# ADuCM4050 register map
Vendor: Analog Devices; Series: ADuCM4050; File version: 1p0
CPU: CM4 r0p1, little endian, MPU, FPU, 3 interrupt priority bits
Registers are 32-bit, read-write, reset 0x0 unless marked. A register's access mark holds for its fields unless they carry their own. Offsets are from the block's base; [hi:lo] are bit positions; {n}, {i} and the like mark numbered series.

## RTC0 — Real-Time Clock
Base 0x40001000
Same registers: RTC1 0x40001400
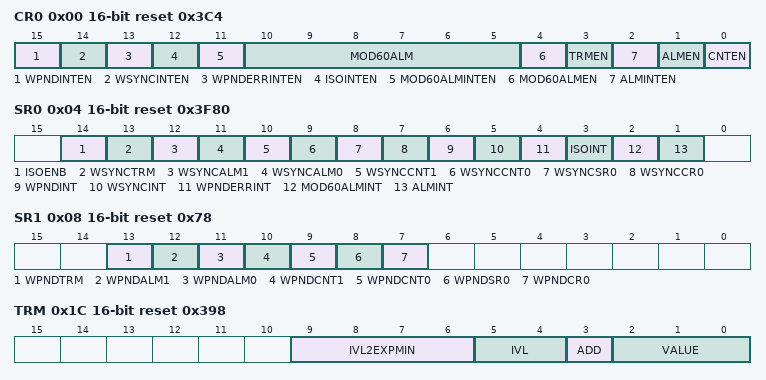
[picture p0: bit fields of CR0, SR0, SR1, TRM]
0x00 CR0 16-bit reset 0x3C4 — RTC Control 0
  [15] WPNDINTEN — Enable Write Pending Sourced Interrupts to the CPU
  [14] WSYNCINTEN — Enable Write Synchronization Sourced Interrupts to the CPU
  [13] WPNDERRINTEN — Enable Write Pending Error Sourced Interrupts to the CPU When an RTC Register-write Pending Error Occurs
  [12] ISOINTEN — Enable ISOINT Sourced Interrupts to the CPU When Isolation of the RTC Power Domain is Activated and Subsequently De-activated
  [11] MOD60ALMINTEN — Enable Periodic Modulo-60 RTC Alarm Sourced Interrupts to the CPU
  [10:5] MOD60ALM range 0x00000000..0x0000003F — Periodic, Modulo-60 Alarm Time in Prescaled RTC Time Units Beyond a Modulo-60 Boundary
  [4] MOD60ALMEN — Enable RTC Modulo-60 Counting of Time Past a Modulo-60 Boundary
  [3] TRMEN — Enable RTC Digital Trimming
  [2] ALMINTEN — Enable ALMINT Sourced Alarm Interrupts to the CPU
  [1] ALMEN — Enable the RTC Alarm (Absolute) Operation
  [0] CNTEN — Global Enable for the RTC
0x04 SR0 16-bit reset 0x3F80 — RTC Status 0
  [14] ISOENB ro — Visibility of 32kHz Sourced Registers
  [13] WSYNCTRM ro — Synchronisation Status of Posted Writes to TRM
  [12] WSYNCALM1 ro — Synchronisation Status of Posted Writes to ALM1
  [11] WSYNCALM0 ro — Synchronisation Status of Posted Writes to ALM0
  [10] WSYNCCNT1 ro — Synchronisation Status of Posted Writes to CNT1
  [9] WSYNCCNT0 ro — Synchronisation Status of Posted Writes to CNT0
  [8] WSYNCSR0 ro — Synchronisation Status of Posted Writes to SR0
  [7] WSYNCCR0 ro — Synchronisation Status of Posted Writes to CR0
  [6] WPNDINT — Write Pending Interrupt
  [5] WSYNCINT — Write Synchronisation Interrupt
  [4] WPNDERRINT — Write Pending Error Interrupt Source
  [3] ISOINT — RTC Power-Domain Isolation Interrupt Source
  [2] MOD60ALMINT — Modulo-60 RTC Alarm Interrupt Source
  [1] ALMINT — Alarm Interrupt Source
0x08 SR1 16-bit reset 0x78 — RTC Status 1
  [13] WPNDTRM ro — Pending Status of Posted Writes to TRM
  [12] WPNDALM1 ro — Pending Status of Posted Writes to ALM1
  [11] WPNDALM0 ro — Pending Status of Posted Writes to ALM0
  [10] WPNDCNT1 ro — Pending Status of Posted Writes to CNT1
  [9] WPNDCNT0 ro — Pending Status of Posted Writes to CNT0
  [8] WPNDSR0 ro — Pending Status of Posted Clearances of Interrupt Sources in SR0
  [7] WPNDCR0 ro — Pending Status of Posted Writes to CR0
0x0C CNT0 16-bit — RTC Count 0
  [15:0] VALUE range 0x00000000..0x0000FFFF — Lower 16 Prescaled (Non-Fractional) Bits of the RTC Real-Time Count
0x10 CNT1 16-bit — RTC Count 1
  [15:0] VALUE range 0x00000000..0x0000FFFF — Upper 16 Prescaled (Non-Fractional) Bits of the RTC Real-Time Count
0x14 ALM0 16-bit reset 0xFFFF — RTC Alarm 0
  [15:0] VALUE range 0x00000000..0x0000FFFF — Lower 16 Prescaled (i.e. Non-Fractional) Bits of the RTC Alarm Target Time
0x18 ALM1 16-bit reset 0xFFFF — RTC Alarm 1
  [15:0] VALUE range 0x00000000..0x0000FFFF — Upper 16 Prescaled (Non-Fractional) Bits of the RTC Alarm Target Time
0x1C TRM 16-bit reset 0x398 — RTC Trim
  [9:6] IVL2EXPMIN range 0x00000000..0x0000000F — Minimum Power-of-two Interval of Prescaled RTC Time Units Which TRM:TRMIVL TRMIVL Can Select
  [5:4] IVL — Trim Interval in Prescaled RTC Time Units
  [3] ADD — Trim Polarity
  [2:0] VALUE — Trim Value in Prescaled RTC Time Units to Be Added or Subtracted from the RTC Count at the End of a Periodic Interval Selected by TRM:TRMIVL
0x20 GWY 16-bit — RTC Gateway
  [15:0] SWKEY wo range 0x00000000..0x0000FFFF — Software-keyed Command Issued by the CPU
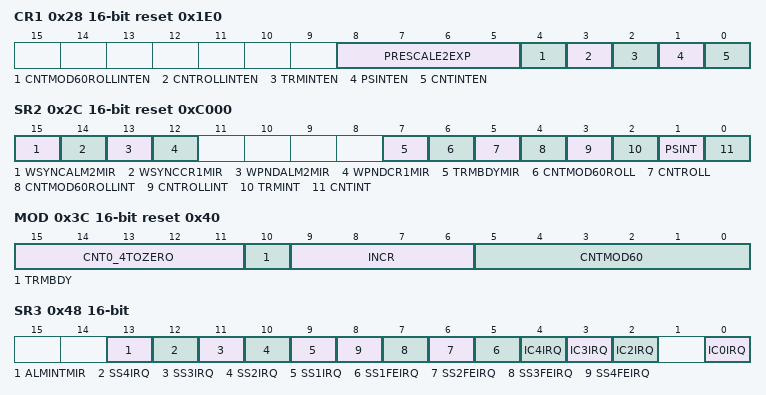
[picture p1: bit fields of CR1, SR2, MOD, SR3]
0x28 CR1 16-bit reset 0x1E0 — RTC Control 1
  [8:5] PRESCALE2EXP — Prescale Power of 2 Division Factor for the RTC Base Clock
  [4] CNTMOD60ROLLINTEN — Enable for the RTC Modulo-60 Count Roll-Over Interrupt Source
  [3] CNTROLLINTEN — Enable for the RTC Count Roll-Over Interrupt Source, in SR2:RTCCNTROLLINT
  [2] TRMINTEN — Enable for the RTC Trim Interrupt Source, in SR2:RTCTRMINT
  [1] PSINTEN — Enable for the Prescaled, Modulo-1 Interrupt Source, in SR2:RTCPSINT
  [0] CNTINTEN — Enable for the RTC Count Interrupt Source
0x2C SR2 16-bit reset 0xC000 — RTC Status 2
  [15] WSYNCALM2MIR ro — Synchronization Status of Posted Writes to ALM2
  [14] WSYNCCR1MIR ro — Synchronization Status of Posted Writes to CR1
  [13] WPNDALM2MIR ro — Pending Status of Posted Writes to ALM2
  [12] WPNDCR1MIR ro — Pending Status of Posted Writes to CR1
  [7] TRMBDYMIR ro — Mirror of MOD:RTCTRMBDY
  [6] CNTMOD60ROLL ro — RTC Count Modulo-60 Roll-Over
  [5] CNTROLL ro — RTC Count Roll-Over
  [4] CNTMOD60ROLLINT — RTC Modulo-60 Count Roll-Over Interrupt Source
  [3] CNTROLLINT — RTC Count Roll-Over Interrupt Source
  [2] TRMINT — RTC Trim Interrupt Source
  [1] PSINT — RTC Prescaled, Modulo-1 Boundary Interrupt Source
  [0] CNTINT — RTC Count Interrupt Source
0x30 SNAP0 16-bit — RTC Snapshot 0
  [15:0] VALUE ro — Constituent Part of the 47-bit Input Capture Channel 0, Containing a Sticky Snapshot of CNT0
0x34 SNAP1 16-bit — RTC Snapshot 1
  [15:0] VALUE ro — Part of the 47-bit Input Capture Channel 0 Containing a Sticky Snapshot of CNT1
0x38 SNAP2 16-bit — RTC Snapshot 2
  [14:0] VALUE ro — Part of the 47-bit Input Capture Channel 0 Containing a Sticky Snapshot of CNT2
0x3C MOD 16-bit reset 0x40 — RTC Modulo
  [15:11] CNT0_4TOZERO ro — Mirror of CNT0[4:0]
  [10] TRMBDY ro — Trim Boundary Indicator
  [9:6] INCR ro — Most Recent Increment Value Added to the RTC Count in CNT1 and CNT0
  [5:0] CNTMOD60 ro — Modulo-60 Value of the RTC Count: CNT1 and CNT0
0x40 CNT2 16-bit — RTC Count 2
  [14:0] VALUE ro — Fractional Bits of the RTC Real-Time Count
0x44 ALM2 16-bit — RTC Alarm 2
  [14:0] VALUE range 0x00000000..0x00007FFF — Fractional Bits of the Alarm Target Time
0x48 SR3 16-bit — RTC Status 3
  [13] ALMINTMIR ro — Read-only Mirror of the SR0:ALMINT Interrupt Source
  [12] SS4IRQ — Sticky Interrupt Source for the SensorStrobe Channel 4
  [11] SS3IRQ — Sticky Interrupt Source for the SensorStrobe Channel 3
  [10] SS2IRQ — Sticky Interrupt Source for the SensorStrobe Channel 2
  [9] SS1IRQ — Sticky Interrupt Source for SensorStrobe Channel 1
  [n+4] SS{n}FEIRQ (n=1..4) — Sticky Interrupt Source for the SensorStrobe Channel {n} Falling Edge
  [4] IC4IRQ — Sticky Interrupt Source for the RTC Input Capture Channel 4
  [3] IC3IRQ — Sticky Interrupt Source for the RTC Input Capture Channel 3
  [2] IC2IRQ — Sticky Interrupt Source for the RTC Input Capture Channel 2
  [0] IC0IRQ — Sticky Interrupt Source for the RTC Input Capture Channel 0
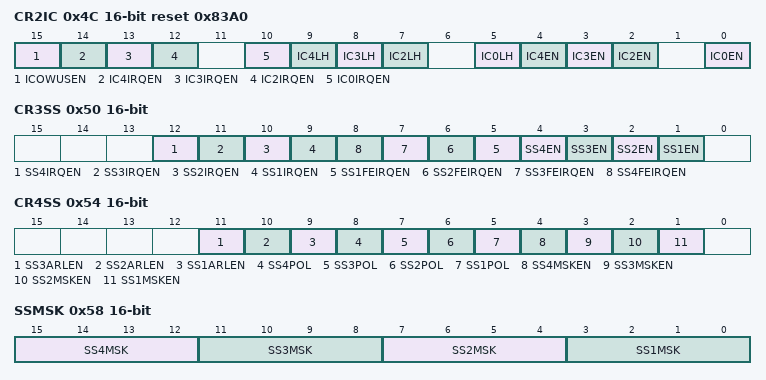
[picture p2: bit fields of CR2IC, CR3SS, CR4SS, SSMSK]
0x4C CR2IC 16-bit reset 0x83A0 — RTC Control 2 for Configuring Input Capture Channels
  [15] ICOWUSEN — Enable Overwrite of Unread Snapshots for All Input Capture Channels
  [14] IC4IRQEN — Interrupt Enable for the RTC Input Capture Channel 4
  [13] IC3IRQEN — Interrupt Enable for the RTC Input Capture Channel 3
  [12] IC2IRQEN — Interrupt Enable for the RTC Input Capture Channel 2
  [10] IC0IRQEN — Interrupt Enable for the RTC Input Capture Channel 0
  [9] IC4LH — Polarity of the Active-going Capture Edge for the Input Capture Channel 4
  [8] IC3LH — Polarity of the Active-going Capture Edge for the Input Capture Channel 3
  [7] IC2LH — Polarity of the Active-going Capture Edge for the Input Capture Channel 2
  [5] IC0LH — Polarity of the Active-Going Capture Edge for the RTC Input Capture Channel 0
  [4] IC4EN — Enable for the RTC Input Capture Channel 4
  [3] IC3EN — Enable for the RTC Input Capture Channel 3
  [2] IC2EN — Enable for the RTC Input Capture Channel 2
  [0] IC0EN — Enable for the RTC Input Capture Channel 0
0x50 CR3SS 16-bit — RTC Control 3 for Configuring SensorStrobe Channel
  [12] SS4IRQEN — Posedge EdgeInterrupt Enable for the SensorStrobe Channel 4
  [11] SS3IRQEN — Posedge EdgeInterrupt Enable for the SensorStrobe Channel 3
  [10] SS2IRQEN — Posedge EdgeInterrupt Enable for the SensorStrobe Channel 2
  [9] SS1IRQEN — Interrupt Enable for SensorStrobe Channel 1
  [n+4] SS{n}FEIRQEN (n=1..4) — Falling Edge Interrupt Enable for the SensorStrobe Channel {n}
  [4] SS4EN — Enable for the SensorStrobe Channel 4
  [3] SS3EN — Enable for the SensorStrobe Channel 3
  [2] SS2EN — Enable for the SensorStrobe Channel 2
  [1] SS1EN — Enable for SensorStrobe Channel 1
0x54 CR4SS 16-bit — RTC Control 4 for Configuring SensorStrobe Channel
  [11] SS3ARLEN — Enable for Fine Control on SensorStrobe Channel 3 Period and Duty Cycle
  [10] SS2ARLEN — Enable for Fine Control on SensorStrobe Channel 2 Period and Duty Cycle
  [9] SS1ARLEN — Enable for Fine Control on SensorStrobe Channel 1 Period and Duty Cycle
  [8] SS4POL — SensorStrobe Channel 4 Polarity Control
  [7] SS3POL — SensorStrobe Channel 3 Polarity Control
  [6] SS2POL — SensorStrobe Channel 2 Polarity Control
  [5] SS1POL — SensorSTrobe Channel 1 Polarity Control
  [4] SS4MSKEN — Enable for Thermometer-Code Masking of the SensorStrobe Channel 4
  [3] SS3MSKEN — Enable for Thermometer-Code Masking of the SensorStrobe Channel 3
  [2] SS2MSKEN — Enable for Thermometer-Code Masking of the SensorStrobe Channel 2
  [1] SS1MSKEN — Enable for Thermometer-Code Masking of the SensorStrobe Channel 1
    0=NO_MSK (Do not apply a mask to SensorStrobe Channel 1 Register); 1=THERM_MSK (Apply thermometer decoded mask)
0x58 SSMSK 16-bit — RTC Mask for SensorStrobe Channel
  [15:12] SS4MSK range 0x00000000..0x0000000F — SensorStrobe Channel 4 Period Control
  [11:8] SS3MSK range 0x00000000..0x0000000F — SensorStrobe Channel 3 Period Control
  [7:4] SS2MSK range 0x00000000..0x0000000F — SensorStrobe Channel 2 Period Control
  [3:0] SS1MSK range 0x00000000..0x0000000F — Concatenation of Thermometer-Encoded Masks for the 16-bit SensorStrobe Channels
{0x5C+4i} IC{i} 16-bit (i=2..4) — RTC Input Capture Channel {i}
  [15:0] IC{i} ro
{0x6C+4i} SS{i} 16-bit reset 0x8000 (i=1..4) — RTC SensorStrobe Channel {i}
  [15:0] SS{i} range 0x00000000..0x0000FFFF — SensorStrobe Channel {i}
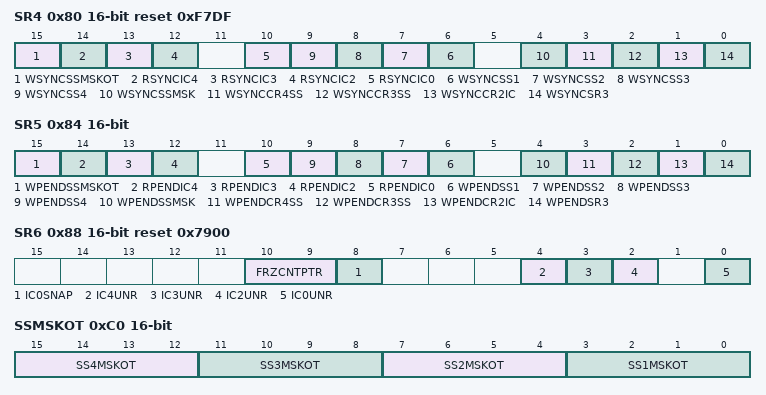
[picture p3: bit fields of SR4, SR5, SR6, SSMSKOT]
0x80 SR4 16-bit reset 0xF7DF — RTC Status 4
  [15] WSYNCSSMSKOT ro — Synchronization Status of Posted Reads Writes to Mask for SensorStrobe Channels on Time Control Register
  [14] RSYNCIC4 ro — Synchronization Status of Posted Reads of RTC Input Channel 4
  [13] RSYNCIC3 ro — Synchronization Status of Posted Reads of RTC Input Channel 3
  [12] RSYNCIC2 ro — Synchronization Status of Posted Reads of RTC Input Channel 2
  [10] RSYNCIC0 ro — Synchronization Status of Posted Reads of RTC Input Channel 0
  [n+5] WSYNCSS{n} ro (n=1..4) — Synchronization Status of Posted Writes to SensorStrobe Channel {n}
  [4] WSYNCSSMSK ro — Synchronization Status of Posted Writes to Masks for SensorStrobe Channel Register
  [3] WSYNCCR4SS ro — Synchronization Status of Posted Writes to RTC Control 4 for Configuring SensorStrobe Channel Register
  [2] WSYNCCR3SS ro — Synchronization Status of Posted Writes to RTC Control 3 for Configuring SensorStrobe Channel Register
  [1] WSYNCCR2IC ro — Synchronization Status of Posted Writes to RTC Control 2 for Configuring Input Capture Channels Register
  [0] WSYNCSR3 ro — Synchronisation Status of Posted Writes to SR3
0x84 SR5 16-bit — RTC Status 5
  [15] WPENDSSMSKOT ro — Pending Status of Posted Writes to RTC Masks for SensorStrobe Channel Register
  [14] RPENDIC4 ro — Pending Status of Posted Reads of IC4
  [13] RPENDIC3 ro — Pending Status of Posted Reads of IC3
  [12] RPENDIC2 ro — Pending Status of Posted Reads of IC2
  [10] RPENDIC0 ro — Pending Status of Posted Reads of Input Capture Channel 0
  [n+5] WPENDSS{n} ro (n=1..4) — Pending Status of Posted Writes to SensorStrobe Channel {n}
  [4] WPENDSSMSK ro — Pending Status of Posted Writes to RTC Masks for SensorStrobe Channel Register
  [3] WPENDCR4SS ro — Pending Status of Posted Writes to RTC Control 4 for Configuring SensorStrobe Channel Register
  [2] WPENDCR3SS ro — Pending Status of Posted Writes to RTC Control 3 for Configuring SensorStrobe Channel Register
  [1] WPENDCR2IC ro — Pending Status of Posted Writes to RTC Control 2 for Configuring Input Capture Channels Register
  [0] WPENDSR3 ro — Pending Status of Posted Clearances of Interrupt Sources in RTC Status 3 Register
0x88 SR6 16-bit reset 0x7900 — RTC Status 6
  [10:9] FRZCNTPTR ro — Pointer for the Triple-Read Sequence of FRZCNT
  [8] IC0SNAP ro — Confirmation That RTC Snapshot 0, 1, 2 Registers Reflect the Value of Input-Capture Channel RTC Input Capture Channel 0
  [4] IC4UNR ro — Sticky Unread Status of the Input Capture Channel 4
  [3] IC3UNR ro — Sticky Unread Status of the Input Capture Channel 3
  [2] IC2UNR ro — Sticky Unread Status of the Input Capture Channel 2
  [0] IC0UNR ro — Sticky Unread Status of the Input Capture Channel 0
0x8C SS1TGT 16-bit reset 0x8000 — RTC SensorStrobe Channel 1 Target
  [15:0] SS1TGT ro — Current Target Value for the SensorStrobe Channel 1
0x90 FRZCNT 16-bit — RTC Freeze Count
  [15:0] FRZCNT ro — RTC Freeze Count. Coherent, Triple 16-Bit Read of the 47-Bit RTC Count
0x94 SS2TGT 16-bit reset 0x8000 — RTC SensorStrobe Channel 2 Target
  [15:0] SS2TGT ro — Current, Cumulative Target Time for SensorStrobe Channel 2, Taking Account of Any Auto-reloading
0x98 SS3TGT 16-bit reset 0x8000 — RTC SensorStrobe Channel 3 Target
  [15:0] SS3TGT ro — Current, Cumulative Target Time for SensorStrobe Channel 3, Taking Account of Any Auto-reloading
{0x9C+4i} SS{i}LOWDUR 16-bit reset 0x8000 (i=1..3) — RTC Auto-Reload Low Duration for SensorStrobe Channel {i}
  [15:0] SS{i}LOWDUR range 0x00000000..0x0000FFFF — Low Duration for SensorStrobe Channel {i}
{0xAC+4i} SS{i}HIGHDUR 16-bit reset 0x8000 (i=1..3) — RTC Auto-Reload High Duration for SensorStrobe Channel {i}
  [15:0] SS{i}HIGHDUR range 0x00000000..0x0000FFFF — High Duration for SensorStrobe Channel {i}
0xC0 SSMSKOT 16-bit — RTC Masks for SensorStrobe Channels on Time Control
  [15:12] SS4MSKOT range 0x00000000..0x0000000F — SensorStrobe Channel 4 on Time Control
  [11:8] SS3MSKOT range 0x00000000..0x0000000F — SensorStrobe Channel 3 on Time Control
  [7:4] SS2MSKOT range 0x00000000..0x0000000F — SensorStrobe Channel 2 on Time Control
  [3:0] SS1MSKOT range 0x00000000..0x0000000F — Concatenation of Thermometer-encoded Masks for the 16-bit SensorStrobe Channels
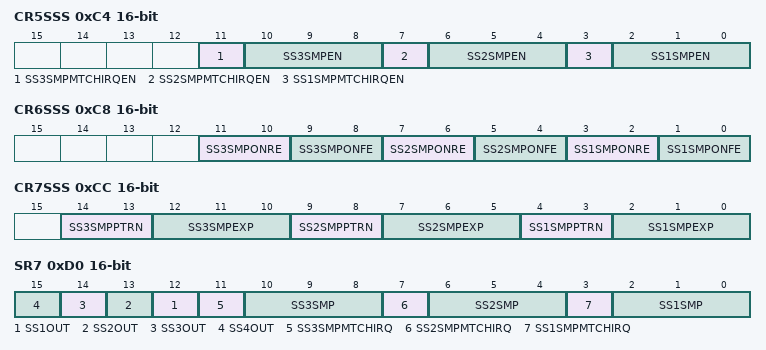
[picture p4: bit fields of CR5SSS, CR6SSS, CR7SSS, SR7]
0xC4 CR5SSS 16-bit — RTC Control 5 for Configuring SensorStrobe Channel GPIO Sampling
  [11] SS3SMPMTCHIRQEN range 0x00000000..0x00000001 — Sample Activity Interrupt Enable for SensorStrobe Channel 3
  [10:8] SS3SMPEN range 0x00000000..0x00000007 — GPIO Input Sample Enable for SensorStrobe Channel 3
  [7] SS2SMPMTCHIRQEN range 0x00000000..0x00000001 — Sample Activity Interrupt Enable for SensorStrobe Channel 2
  [6:4] SS2SMPEN range 0x00000000..0x00000007 — GPIO Input Sample Enable for SensorStrobe Channel 2
  [3] SS1SMPMTCHIRQEN range 0x00000000..0x00000001 — Sample Activity Interrupt Enable for SensorStrobe Channel 1
  [2:0] SS1SMPEN range 0x00000000..0x00000007 — GPIO Input Sample Enable for SensorStrobe Channel 1
0xC8 CR6SSS 16-bit — RTC Control 6 for Configuring SensorStrobe Channel GPIO Sampling Edge
  [11:10] SS3SMPONRE — GPIO Sample Around Rising Edge of SensorStrobe Channel 3
    0=SS3NORES (No sampling of input around rising edge); 1=SS3BRES (Input sampled one clock cycle before rising edge of the SensorStrobe channel 3); 2=SS3RES (Input sampled at rising edge of the SensorStrobe channel 3); 3=SS3ARES (Input sampled one clock cycle after rising edge of the SensorStrobe channel 3)
  [9:8] SS3SMPONFE — GPIO Sample Around Falling Edge of SensorStrobe Channel 3
    0=SS3NOFES (No sampling of input around falling edge); 1=SS3BFES (Input sampled one clock cycle before falling edge of the SensorStrobe channel 3); 2=SS3FES (Input sampled at falling edge of the SensorStrobe channel 3); 3=SS3AFES (Input sampled one clock cycle after falling edge of the SensorStrobe channel 3)
  [7:6] SS2SMPONRE — GPIO Sample Around Rising Edge of SensorStrobe Channel 2
    0=SS2NORES (No sampling of input around rising edge); 1=SS2BRES (Input sampled one clock cycle before rising edge of the SensorStrobe channel 2); 2=SS2RES (Input sampled at rising edge of the SensorStrobe channel 2); 3=SS2ARES (Input sampled one clock cycle after rising edge of the SensorStrobe channel 2)
  [5:4] SS2SMPONFE — GPIO Sample Around Falling Edge of SensorStrobe Channel 2
    0=SS2NOFES (No sampling of input around falling edge); 1=SS2BFES (Input sampled one clock cycle before falling edge of the SensorStrobe channel 2); 2=SS2FES (Input sampled at falling edge of the SensorStrobe channel 2); 3=SS2AFES (Input sampled one clock cycle after falling edge of the SensorStrobe channel 2)
  [3:2] SS1SMPONRE — GPIO Sample Around Rising Edge of SensorStrobe Channel 1
    0=SS1NORES (No sampling of input around rising edge); 1=SS1BRES (Input sampled one clock cycle before rising edge of the SensorStrobe channel 1); 2=SS1RES (Input sampled at rising edge of the SensorStrobe channel 1); 3=SS1ARES (Input sampled one clock cycle after rising edge of the SensorStrobe channel 1)
  [1:0] SS1SMPONFE — GPIO Sample Around Falling Edge of SensorStrobe Channel 1
    0=SS1NOFES (No sampling of input around falling edge); 1=SS1BFES (Input sampled one clock cycle before falling edge of the SensorStrobe channel 1); 2=SS1FES (Input sampled at falling edge of the SensorStrobe channel 1); 3=SS1AFES (Input sampled one clock cycle after falling edge of the SensorStrobe channel 1)
0xCC CR7SSS 16-bit — RTC Control 7 for Configuring SensorStrobe Channel GPIO Sampling Activity
  [14:13] SS3SMPPTRN — Sample Activity Selection for SensorStrobe Channel 3
    0=SS3SMPCHNG (Current GPIO sample is not same as previous sample); 1=SS3SMPSAME (Current GPIO sample is same as previous sample); 2=SS3SMPMTCH (Current GPIO sample is same as expected sample); 3=SS3SMPNOMTCH (Current GPIO sample is not same as expected sample)
  [12:10] SS3SMPEXP range 0x00000000..0x00000007 — Expected GPIO Sample for SensorStrobe Channel 3
  [9:8] SS2SMPPTRN — Sample Activity Selection for SensorStrobe Channel 2
    0=SS2SMPCHNG (Current GPIO sample is not same as previous sample); 1=SS2SMPSAME (Current GPIO sample is same as previous sample); 2=SS2SMPMTCH (Current GPIO sample is same as expected sample); 3=SS2SMPNOMTCH (Current GPIO sample is not same as expected sample)
  [7:5] SS2SMPEXP range 0x00000000..0x00000007 — Expected GPIO Sample for SensorStrobe Channel 2
  [4:3] SS1SMPPTRN — Sample Activity Selection for SensorStrobe Channel 1
    0=SS1SMPCHNG (Current GPIO sample is not same as previous sample); 1=SS1SMPSAME (Current GPIO sample is same as previous sample); 2=SS1SMPMTCH (Current GPIO sample is same as expected sample); 3=SS1SMPNOMTCH (Current GPIO sample is not same as expected sample)
  [2:0] SS1SMPEXP range 0x00000000..0x00000007 — Expected GPIO Sample for SensorStrobe Channel 1
0xD0 SR7 16-bit — RTC Status 7
  [n+11] SS{n}OUT ro (n=1..4) — Output Value for SensorStrobe Channel {n}
  [11] SS3SMPMTCHIRQ range 0x00000000..0x00000001 — Sticky Status of GPIO Sample Pattern Match for SensorStrobe Channel 3
  [10:8] SS3SMP ro — Latest GPIO Sample for SensorStrobe Channel 3
  [7] SS2SMPMTCHIRQ range 0x00000000..0x00000001 — Sticky Status of GPIO Sample Pattern Match for SensorStrobe Channel 2
  [6:4] SS2SMP ro — Latest GPIO Sample for SensorStrobe Channel 2
  [3] SS1SMPMTCHIRQ range 0x00000000..0x00000001 — Sticky Status of GPIO Sample Pattern Match for SensorStrobe Channel 1
  [2:0] SS1SMP ro — Latest GPIO Sample for SensorStrobe Channel 1
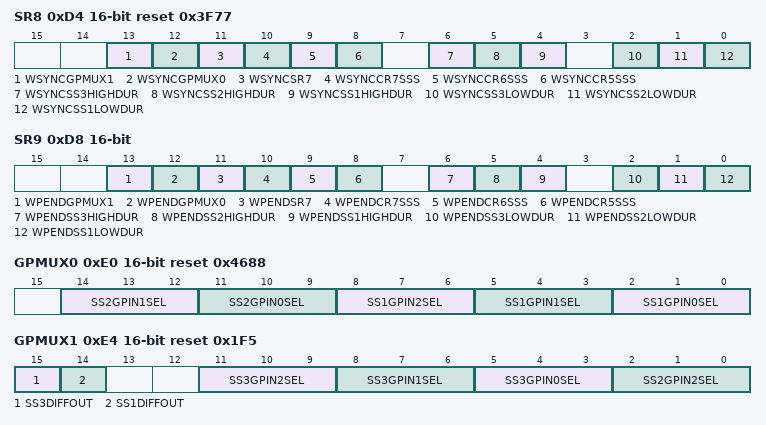
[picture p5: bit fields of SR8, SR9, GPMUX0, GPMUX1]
0xD4 SR8 16-bit reset 0x3F77 — RTC Status 8
  [13] WSYNCGPMUX1 ro — Synchronisation Status of Posted Writes to GPIO Pin Mux Control Register 1
  [12] WSYNCGPMUX0 ro — Synchronisation Status of Posted Writes to GPIO Pin Mux Control Register 0
  [11] WSYNCSR7 ro — Synchronisation Status of Posted Writes to Status 7 Register
  [10] WSYNCCR7SSS ro — Synchronisation Status of Posted Writes to Control 7 for Configuring SensorStrobe Channel Register
  [9] WSYNCCR6SSS ro — Synchronisation Status of Posted Writes to Control 6 for Configuring SensorStrobe Channel Register
  [8] WSYNCCR5SSS ro — Synchronisation Status of Posted Writes to Control 5 for Configuring SensorStrobe Channel Register
  [6] WSYNCSS3HIGHDUR ro — Synchronisation Status of Posted Writes to SensorStrobe Channel 3 High Duration Register
  [5] WSYNCSS2HIGHDUR ro — Synchronisation Status of Posted Writes to SensorStrobe Channel 2 High Duration Register
  [4] WSYNCSS1HIGHDUR ro — Synchronisation Status of Posted Writes to SensorStrobe Channel 1 High Duration Register
  [2] WSYNCSS3LOWDUR ro — Synchronisation Status of Posted Writes to SensorStrobe Channel 3 Low Duration Register
  [1] WSYNCSS2LOWDUR ro — Synchronisation Status of Posted Writes to SensorStrobe Channel 2 Low Duration Register
  [0] WSYNCSS1LOWDUR ro — Synchronisation Status of Posted Writes to SensorStrobe Channel 1 Low Duration Register
0xD8 SR9 16-bit — RTC Status 9
  [13] WPENDGPMUX1 ro — Pending Status of Posted Writes to GPMUX1
  [12] WPENDGPMUX0 ro — Pending Status of Posted Writes to GPMUX0
  [11] WPENDSR7 ro — Pending Status of Posted Writes to SR7
  [10] WPENDCR7SSS ro — Pending Status of Posted Writes to Control 7 for Configuring SensorStrobe Channel Register
  [9] WPENDCR6SSS ro — Pending Status of Posted Writes to Control 6 for Configuring SensorStrobe Channel Register
  [8] WPENDCR5SSS ro — Pending Status of Posted Writes to Control 5 for Configuring SensorStrobe Channel Register
  [6] WPENDSS3HIGHDUR ro — Pending Status of Posted Writes to SensortStrobe Channel 3 High Duration Register
  [5] WPENDSS2HIGHDUR ro — Pending Status of Posted Writes to SensortStrobe Channel 2 High Duration Register
  [4] WPENDSS1HIGHDUR ro — Pending Status of Posted Writes to SensortStrobe Channel 1 High Duration Register
  [2] WPENDSS3LOWDUR ro — Pending Status of Posted Writes to SensortStrobe Channel 3 Low Duration Register
  [1] WPENDSS2LOWDUR ro — Pending Status of Posted Writes to SensortStrobe Channel 2 Low Duration Register
  [0] WPENDSS1LOWDUR ro — Pending Status of Posted Writes to SensortStrobe Channel 1 Low Duration Register
0xE0 GPMUX0 16-bit reset 0x4688 — RTC GPIO Pin Mux Control Register 0
  [14:12] SS2GPIN1SEL range 0x00000000..0x00000007 — GPIO Mux Selection for SensorStrobe Channel 2 Input 1
  [11:9] SS2GPIN0SEL range 0x00000000..0x00000007 — GPIO Mux Selection for SensorStrobe Channel 2 Input 0
  [8:6] SS1GPIN2SEL range 0x00000000..0x00000007 — GPIO Mux Selection for SensorStrobe Channel 1 Input 2
  [5:3] SS1GPIN1SEL range 0x00000000..0x00000007 — GPIO Mux Selection for SensorStrobe Channel 1 Input 1
  [2:0] SS1GPIN0SEL range 0x00000000..0x00000007 — GPIO Mux Selection for SensorStrobe Channel 1 Input0
0xE4 GPMUX1 16-bit reset 0x1F5 — RTC GPIO Pin Mux Control Register 1
  [15] SS3DIFFOUT range 0x00000000..0x00000001 — Differential SensorStrobe Out Option for SensorStrobe Channel 3
  [14] SS1DIFFOUT range 0x00000000..0x00000001 — Differential SensorStrobe Out Option for SensorStrobe Channel 1
  [11:9] SS3GPIN2SEL range 0x00000000..0x00000007 — GPIO Mux Selection for SensorStrobe Channel 3 Input 2
  [8:6] SS3GPIN1SEL range 0x00000000..0x00000007 — GPIO Mux Selection for SensorStrobe Channel 3 Input 1
  [5:3] SS3GPIN0SEL range 0x00000000..0x00000007 — GPIO Mux Selection for SensorStrobe Channel 3 Input 0
  [2:0] SS2GPIN2SEL range 0x00000000..0x00000007 — GPIO Mux Selection for SensorStrobe Channel 2 Input 2
